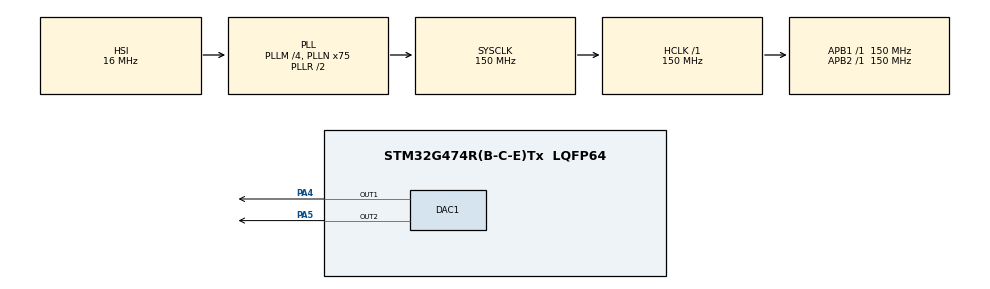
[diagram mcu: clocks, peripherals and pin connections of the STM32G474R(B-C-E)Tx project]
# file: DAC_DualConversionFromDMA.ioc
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DAC1.DAC_Channel-DAC_OUT2=DAC_CHANNEL_2
DAC1.DAC_Trigger_OUT1-DAC_OUT1=DAC_TRIGGER_T2_TRGO
DAC1.DAC_Trigger_OUT2-DAC_OUT2=DAC_TRIGGER_T2_TRGO
Dma.DAC1_CH1.0.Direction=DMA_MEMORY_TO_PERIPH
Dma.DAC1_CH1.0.EventEnable=DISABLE
Dma.DAC1_CH1.0.Instance=DMA1_Channel1
Dma.DAC1_CH1.0.MemDataAlignment=DMA_MDATAALIGN_WORD
Dma.DAC1_CH1.0.MemInc=DMA_MINC_ENABLE
Dma.DAC1_CH1.0.Mode=DMA_CIRCULAR
Dma.DAC1_CH1.0.PeriphDataAlignment=DMA_PDATAALIGN_WORD
Dma.DAC1_CH1.0.PeriphInc=DMA_PINC_DISABLE
Dma.DAC1_CH1.0.Polarity=HAL_DMAMUX_REQ_GEN_RISING
Dma.DAC1_CH1.0.Priority=DMA_PRIORITY_LOW
Dma.DAC1_CH1.0.RequestNumber=1
Dma.DAC1_CH1.0.SignalID=NONE
Dma.DAC1_CH1.0.SyncEnable=DISABLE
Dma.DAC1_CH1.0.SyncPolarity=HAL_DMAMUX_SYNC_NO_EVENT
Dma.DAC1_CH1.0.SyncRequestNumber=1
Dma.DAC1_CH1.0.SyncSignalID=NONE
Dma.Request0=DAC1_CH1
Mcu.Family=STM32G4
Mcu.Name=STM32G474R(B-C-E)Tx
Mcu.Package=LQFP64
NVIC.DMA1_Channel1_IRQn=true\:0\:0\:false\:false\:true\:false\:true\:true
NVIC.PriorityGroup=NVIC_PRIORITYGROUP_4
PA4.Signal=COMP_DAC11_group
PA5.Signal=COMP_DAC12_group
ProjectManager.HeapSize=0x200
ProjectManager.StackSize=0x400
ProjectManager.TargetToolchain=EWARM V8.32
RCC.ADC12Freq_Value=150000000
RCC.ADC345Freq_Value=150000000
RCC.AHBFreq_Value=150000000
RCC.APB1Freq_Value=150000000
RCC.APB1TimFreq_Value=150000000
RCC.APB2Freq_Value=150000000
RCC.APB2TimFreq_Value=150000000
RCC.CortexFreq_Value=150000000
RCC.EXTERNAL_CLOCK_VALUE=12288000
RCC.HCLKFreq_Value=150000000
RCC.HSE_VALUE=24000000
RCC.HSI48_VALUE=16000000
RCC.HSI_VALUE=16000000
RCC.LSE_VALUE=32768
RCC.PLLM=RCC_PLLM_DIV4
RCC.PLLN=75
RCC.SYSCLKFreq_VALUE=150000000
RCC.SYSCLKSource=RCC_SYSCLKSOURCE_PLLCLK
RCC.USBFreq_Value=150000000
RCC.VCOOutputFreq_Value=300000000
SH.COMP_DAC11_group.0=DAC1_OUT1,DAC_OUT1
SH.COMP_DAC12_group.0=DAC1_OUT2,DAC_OUT2
TIM2.AutoReloadPreload=TIM_AUTORELOAD_PRELOAD_DISABLE
TIM2.ClockDivision=TIM_CLOCKDIVISION_DIV1
TIM2.CounterMode=TIM_COUNTERMODE_UP
TIM2.Dithering=Disable
TIM2.PeriodNoDither=999
TIM2.Prescaler=149
TIM2.TIM_MasterOutputTrigger=TIM_TRGO_UPDATE
TIM2.TIM_MasterSlaveMode=TIM_MASTERSLAVEMODE_DISABLE
VP_SYS_VS_DBSignals.Mode=DisableDeadBatterySignals
VP_TIM2_VS_ClockSourceINT.Mode=Internal
board=custom

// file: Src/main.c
/* USER CODE BEGIN Header */
/**
  ******************************************************************************
  * @file    Examples/DAC/DAC_DualConversionFromDMA/Src/main.c
  * @author  MCD Application Team
  * @brief   This example provides a short description of how to use the DAC
  *          dual channel mode with DMA to generate signal on both DAC channels
  *          at the same time.
  ******************************************************************************
  * @attention
  *
  * Copyright (c) 2019-2021 STMicroelectronics.
  * All rights reserved.
  *
  * This software is licensed under terms that can be found in the LICENSE file
  * in the root directory of this software component.
  * If no LICENSE file comes with this software, it is provided AS-IS.
  *
  ******************************************************************************
  */
/* USER CODE END Header */
#include "main.h"

DAC_HandleTypeDef hdac1;
DMA_HandleTypeDef hdma_dac1_ch1;

TIM_HandleTypeDef htim2;

/* USER CODE BEGIN PV */
/* Private variables ---------------------------------------------------------*/

uint32_t wave[4] = {0x07FF0000, 0x0FFF07FF, 0x07FF0FFF, 0x000007FF};

/* USER CODE END PV */

void SystemClock_Config(void);
static void MX_GPIO_Init(void);
static void MX_DMA_Init(void);
static void MX_DAC1_Init(void);
static void MX_TIM2_Init(void);

int main(void)
{

  /* MCU Configuration--------------------------------------------------------*/

  /* Reset of all peripherals, Initializes the Flash interface and the Systick. */
  HAL_Init();

  /* Configure the system clock */
  SystemClock_Config();

  /* Initialize all configured peripherals */
  MX_GPIO_Init();
  MX_DMA_Init();
  MX_DAC1_Init();
  MX_TIM2_Init();
  /* USER CODE BEGIN 2 */

  /* Initialize LED on board */
  BSP_LED_Init(LED4);

  /* USER CODE END 2 */

  /* Infinite loop */
  /* USER CODE BEGIN WHILE */

  /* Set initial DAC values to convert */
  if (HAL_DACEx_DualSetValue(&hdac1, DAC_ALIGN_12B_R, 0, 0) != HAL_OK)
  {
    /* DAC value set error */
    Error_Handler();
  }

  /* Start Timer trigger */
  if (HAL_TIM_Base_Start(&htim2) != HAL_OK)
  {
    /* Counter enable error */
    Error_Handler();
  }

  /* Start DAC converters */
  if (HAL_DACEx_DualStart_DMA(&hdac1, DAC_CHANNEL_1, wave, sizeof(wave)/sizeof(wave[0]), DAC_ALIGN_12B_R) != HAL_OK)
  {
    /* DAC conversion start error */
    Error_Handler();
  }

  BSP_LED_On(LED4);
  while (1)
  {
    /* USER CODE END WHILE */

  }
}

void SystemClock_Config(void)
{
  RCC_OscInitTypeDef RCC_OscInitStruct = {0};
  RCC_ClkInitTypeDef RCC_ClkInitStruct = {0};

  /** Configure the main internal regulator output voltage
  */
  HAL_PWREx_ControlVoltageScaling(PWR_REGULATOR_VOLTAGE_SCALE1);

  /** Initializes the RCC Oscillators according to the specified parameters
  * in the RCC_OscInitTypeDef structure.
  */
  RCC_OscInitStruct.OscillatorType = RCC_OSCILLATORTYPE_HSI;
  RCC_OscInitStruct.HSIState = RCC_HSI_ON;
  RCC_OscInitStruct.HSICalibrationValue = RCC_HSICALIBRATION_DEFAULT;
  RCC_OscInitStruct.PLL.PLLState = RCC_PLL_ON;
  RCC_OscInitStruct.PLL.PLLSource = RCC_PLLSOURCE_HSI;
  RCC_OscInitStruct.PLL.PLLM = RCC_PLLM_DIV4;
  RCC_OscInitStruct.PLL.PLLN = 75;
  RCC_OscInitStruct.PLL.PLLP = RCC_PLLP_DIV2;
  RCC_OscInitStruct.PLL.PLLQ = RCC_PLLQ_DIV2;
  RCC_OscInitStruct.PLL.PLLR = RCC_PLLR_DIV2;
  if (HAL_RCC_OscConfig(&RCC_OscInitStruct) != HAL_OK)
  {
    Error_Handler();
  }

  /** Initializes the CPU, AHB and APB buses clocks
  */
  RCC_ClkInitStruct.ClockType = RCC_CLOCKTYPE_HCLK|RCC_CLOCKTYPE_SYSCLK
                              |RCC_CLOCKTYPE_PCLK1|RCC_CLOCKTYPE_PCLK2;
  RCC_ClkInitStruct.SYSCLKSource = RCC_SYSCLKSOURCE_PLLCLK;
  RCC_ClkInitStruct.AHBCLKDivider = RCC_SYSCLK_DIV1;
  RCC_ClkInitStruct.APB1CLKDivider = RCC_HCLK_DIV1;
  RCC_ClkInitStruct.APB2CLKDivider = RCC_HCLK_DIV1;

  if (HAL_RCC_ClockConfig(&RCC_ClkInitStruct, FLASH_LATENCY_4) != HAL_OK)
  {
    Error_Handler();
  }
}

static void MX_DAC1_Init(void)
{

  DAC_ChannelConfTypeDef sConfig = {0};

  /** DAC Initialization
  */
  hdac1.Instance = DAC1;
  if (HAL_DAC_Init(&hdac1) != HAL_OK)
  {
    Error_Handler();
  }

  /** DAC channel OUT1 config
  */
  sConfig.DAC_HighFrequency = DAC_HIGH_FREQUENCY_INTERFACE_MODE_AUTOMATIC;
  sConfig.DAC_DMADoubleDataMode = DISABLE;
  sConfig.DAC_SignedFormat = DISABLE;
  sConfig.DAC_SampleAndHold = DAC_SAMPLEANDHOLD_DISABLE;
  sConfig.DAC_Trigger = DAC_TRIGGER_T2_TRGO;
  sConfig.DAC_Trigger2 = DAC_TRIGGER_NONE;
  sConfig.DAC_OutputBuffer = DAC_OUTPUTBUFFER_ENABLE;
  sConfig.DAC_ConnectOnChipPeripheral = DAC_CHIPCONNECT_EXTERNAL;
  sConfig.DAC_UserTrimming = DAC_TRIMMING_FACTORY;
  if (HAL_DAC_ConfigChannel(&hdac1, &sConfig, DAC_CHANNEL_1) != HAL_OK)
  {
    Error_Handler();
  }

  /** DAC channel OUT2 config
  */
  if (HAL_DAC_ConfigChannel(&hdac1, &sConfig, DAC_CHANNEL_2) != HAL_OK)
  {
    Error_Handler();
  }
  /* USER CODE BEGIN DAC1_Init 2 */
  /** DAC calibration
  */
  if (HAL_DACEx_SelfCalibrate(&hdac1, &sConfig, DAC_CHANNEL_1) != HAL_OK)
  {
    Error_Handler();
  }
  if (HAL_DACEx_SelfCalibrate(&hdac1, &sConfig, DAC_CHANNEL_2) != HAL_OK)
  {
    Error_Handler();
  }
  /* USER CODE END DAC1_Init 2 */

}

static void MX_TIM2_Init(void)
{

  TIM_ClockConfigTypeDef sClockSourceConfig = {0};
  TIM_MasterConfigTypeDef sMasterConfig = {0};

  htim2.Instance = TIM2;
  htim2.Init.Prescaler = 149;
  htim2.Init.CounterMode = TIM_COUNTERMODE_UP;
  htim2.Init.Period = 999;
  htim2.Init.ClockDivision = TIM_CLOCKDIVISION_DIV1;
  htim2.Init.AutoReloadPreload = TIM_AUTORELOAD_PRELOAD_DISABLE;
  if (HAL_TIM_Base_Init(&htim2) != HAL_OK)
  {
    Error_Handler();
  }
  sClockSourceConfig.ClockSource = TIM_CLOCKSOURCE_INTERNAL;
  if (HAL_TIM_ConfigClockSource(&htim2, &sClockSourceConfig) != HAL_OK)
  {
    Error_Handler();
  }
  sMasterConfig.MasterOutputTrigger = TIM_TRGO_UPDATE;
  sMasterConfig.MasterSlaveMode = TIM_MASTERSLAVEMODE_DISABLE;
  if (HAL_TIMEx_MasterConfigSynchronization(&htim2, &sMasterConfig) != HAL_OK)
  {
    Error_Handler();
  }

}

static void MX_DMA_Init(void)
{

  /* DMA controller clock enable */
  __HAL_RCC_DMAMUX1_CLK_ENABLE();
  __HAL_RCC_DMA1_CLK_ENABLE();

  /* DMA interrupt init */
  /* DMA1_Channel1_IRQn interrupt configuration */
  HAL_NVIC_SetPriority(DMA1_Channel1_IRQn, 0, 0);
  HAL_NVIC_EnableIRQ(DMA1_Channel1_IRQn);

}

static void MX_GPIO_Init(void)
{

  /* GPIO Ports Clock Enable */
  __HAL_RCC_GPIOA_CLK_ENABLE();

}

void Error_Handler(void)
{
  /* USER CODE BEGIN Error_Handler_Debug */
  /* User can add his own implementation to report the HAL error return state */
  while(1)
  {
    /* Toggle LED4 */
    BSP_LED_Off(LED4);
    HAL_Delay(800);
    BSP_LED_On(LED4);
    HAL_Delay(10);
    BSP_LED_Off(LED4);
    HAL_Delay(180);
    BSP_LED_On(LED4);
    HAL_Delay(10);
  }
  /* USER CODE END Error_Handler_Debug */
}

#ifdef  USE_FULL_ASSERT
/**
  * @brief  Reports the name of the source file and the source line number
  *         where the assert_param error has occurred.
  * @param  file: pointer to the source file name
  * @param  line: assert_param error line source number
  * @retval None
  */
void assert_failed(uint8_t *file, uint32_t line)
{
  /* USER CODE BEGIN 6 */
  /* User can add his own implementation to report the file name and line number,
     tex: printf("Wrong parameters value: file %s on line %d\r\n", file, line) */
  Error_Handler();
  /* USER CODE END 6 */
}
#endif /* USE_FULL_ASSERT */
